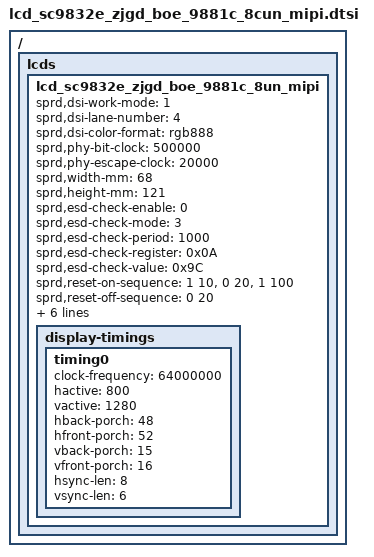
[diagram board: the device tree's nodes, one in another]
/ { lcds {
	lcd_sc9832e_zjgd_boe_9881c_8un_mipi: lcd_sc9832e_zjgd_boe_9881c_8un_mipi {

		sprd,dsi-work-mode = <1>;
		sprd,dsi-lane-number = <4>;
		sprd,dsi-color-format = "rgb888";

		sprd,phy-bit-clock = <500000>;
		sprd,phy-escape-clock = <20000>;

		sprd,width-mm = <68>;
		sprd,height-mm = <121>;

		sprd,esd-check-enable = <0>;
		sprd,esd-check-mode = <3>;
		sprd,esd-check-period = <1000>;
		sprd,esd-check-register = <0x0A>;
		sprd,esd-check-value = <0x9C>;

		sprd,reset-on-sequence = <1 10>, <0 20>, <1 100>;
		sprd,reset-off-sequence = <0 20>;

		sprd,initial-command = [
		 39 00 00 04 FF 98 81 03 
//GIP_1

		 23 00 00 02 01 00 
		 23 00 00 02 02 00 
		 23 00 00 02 03 73 
		 23 00 00 02 04 D7 
		 23 00 00 02 05 00 
		 23 00 00 02 06 08 
		 23 00 00 02 07 11 
		 23 00 00 02 08 00 
		 23 00 00 02 09 3F 
		 23 00 00 02 0a 00 
		 23 00 00 02 0b 00 
		 23 00 00 02 0c 00 
		 23 00 00 02 0d 00 
		 23 00 00 02 0e 00 
		 23 00 00 02 0f 3F 
		 23 00 00 02 10 3F 
		 23 00 00 02 11 00         
		 23 00 00 02 12 00 
		 23 00 00 02 13 00 
		 23 00 00 02 14 00 
		 23 00 00 02 15 00 
		 23 00 00 02 16 00 
		 23 00 00 02 17 00 
		 23 00 00 02 18 00 
		 23 00 00 02 19 00 
		 23 00 00 02 1a 00 
		 23 00 00 02 1b 00 
		 23 00 00 02 1c 00 
		 23 00 00 02 1d 00 
		 23 00 00 02 1e 40 
		 23 00 00 02 1f 80 
		 23 00 00 02 20 06 
		 23 00 00 02 21 01 
		 23 00 00 02 22 00 
		 23 00 00 02 23 00 
		 23 00 00 02 24 00 
		 23 00 00 02 25 00 
		 23 00 00 02 26 00 
		 23 00 00 02 27 00 
		 23 00 00 02 28 33 
		 23 00 00 02 29 33 
		 23 00 00 02 2a 00 
		 23 00 00 02 2b 00 
		 23 00 00 02 2c 00 
		 23 00 00 02 2d 00 
		 23 00 00 02 2e 00 
		 23 00 00 02 2f 00 
		 23 00 00 02 30 00 
		 23 00 00 02 31 00 
		 23 00 00 02 32 00 
		 23 00 00 02 33 00 
		 23 00 00 02 34 00 
		 23 00 00 02 35 00 
		 23 00 00 02 36 00 
		 23 00 00 02 37 00 
		 23 00 00 02 38 00 
		 23 00 00 02 39 00 
		 23 00 00 02 3a 00 
		 23 00 00 02 3b 00 
		 23 00 00 02 3c 00 
		 23 00 00 02 3d 00 
		 23 00 00 02 3e 00 
		 23 00 00 02 3f 00 
		 23 00 00 02 40 00 
		 23 00 00 02 41 00 
		 23 00 00 02 42 00 
		 23 00 00 02 43 00 
		 23 00 00 02 44 00 


//GIP_2
		 23 00 00 02 50 01 
		 23 00 00 02 51 23 
		 23 00 00 02 52 44 
		 23 00 00 02 53 67 
		 23 00 00 02 54 89 
		 23 00 00 02 55 ab 
		 23 00 00 02 56 01 
		 23 00 00 02 57 23 
		 23 00 00 02 58 45 
		 23 00 00 02 59 67 
		 23 00 00 02 5a 89 
		 23 00 00 02 5b ab 
		 23 00 00 02 5c cd 
		 23 00 00 02 5d ef 

//GIP_3
		 23 00 00 02 5e 00 
		 23 00 00 02 5f 0C 
		 23 00 00 02 60 0C 
		 23 00 00 02 61 0F 
		 23 00 00 02 62 0F 
		 23 00 00 02 63 0E 
		 23 00 00 02 64 0E 
		 23 00 00 02 65 06 
		 23 00 00 02 66 07 
		 23 00 00 02 67 0D 
		 23 00 00 02 68 02 
		 23 00 00 02 69 02 
		 23 00 00 02 6a 02 
		 23 00 00 02 6b 02 
		 23 00 00 02 6c 02 
		 23 00 00 02 6d 02 
		 23 00 00 02 6e 0D 
		 23 00 00 02 6f 02 
		 23 00 00 02 70 02 
		 23 00 00 02 71 05 
		 23 00 00 02 72 01 
		 23 00 00 02 73 08 
		 23 00 00 02 74 00 
  
		 23 00 00 02 75 0C 
		 23 00 00 02 76 0C 
		 23 00 00 02 77 0F    
		 23 00 00 02 78 0F 
		 23 00 00 02 79 0E 
		 23 00 00 02 7a 0E 
		 23 00 00 02 7b 06 
		 23 00 00 02 7c 07 
		 23 00 00 02 7d 0D 
		 23 00 00 02 7e 02 
		 23 00 00 02 7f 02 
		 23 00 00 02 80 02  
		 23 00 00 02 81 02 
		 23 00 00 02 82 02 
		 23 00 00 02 83 02 
		 23 00 00 02 84 0D   
		 23 00 00 02 85 02 
		 23 00 00 02 86 02 
		 23 00 00 02 87 05 
		 23 00 00 02 88 01 
		 23 00 00 02 89 08 
		 23 00 00 02 8A 00 



//CMD_Page 4
		 39 00 00 04 FF 98 81 04 

		 23 00 00 02 6E 3B 
		 23 00 00 02 6F 57 
		 23 00 00 02 3A A4 
		 23 00 00 02 8D 1F 
		 23 00 00 02 87 BA 
		 23 00 00 02 B2 D1 
		 23 00 00 02 88 0B 
		 23 00 00 02 38 01 
		 23 00 00 02 39 00 
		 23 00 00 02 B5 07 
		 23 00 00 02 31 75 
		 23 00 00 02 3B 98 
			
//CMD_Page 1
		 39 00 00 04 FF 98 81 01 
		 23 00 00 02 22 0A 
		 23 00 00 02 31 09 
		 23 00 00 02 53 62 
		 23 00 00 02 55 40 
		 23 00 00 02 50 86 
		 23 00 00 02 51 82 
		 23 00 00 02 60 27 
		 23 00 00 02 62 20 


//============Gamma START=============

		 23 00 00 02 A0 00 
		 23 00 00 02 A1 11 
		 23 00 00 02 A2 1F 
		 23 00 00 02 A3 13 
		 23 00 00 02 A4 14 
		 23 00 00 02 A5 28 
		 23 00 00 02 A6 1D 
		 23 00 00 02 A7 1F 
		 23 00 00 02 A8 7A 
		 23 00 00 02 A9 1C 
		 23 00 00 02 AA 2A 
		 23 00 00 02 AB 69 
		 23 00 00 02 AC 1A 
		 23 00 00 02 AD 18 
		 23 00 00 02 AE 4D 
		 23 00 00 02 AF 22 
		 23 00 00 02 B0 29 
		 23 00 00 02 B1 4C 
		 23 00 00 02 B2 5B 
		 23 00 00 02 B3 23 



//Neg Register
		 23 00 00 02 C0 00 
		 23 00 00 02 C1 12 
		 23 00 00 02 C2 1F 
		 23 00 00 02 C3 12 
		 23 00 00 02 C4 15 
		 23 00 00 02 C5 29 
		 23 00 00 02 C6 1D 
		 23 00 00 02 C7 1E 
		 23 00 00 02 C8 78 
		 23 00 00 02 C9 1D 
		 23 00 00 02 CA 29 
		 23 00 00 02 CB 69 
		 23 00 00 02 CC 19 
		 23 00 00 02 CD 18 
		 23 00 00 02 CE 4C 
		 23 00 00 02 CF 21 
		 23 00 00 02 D0 29 
		 23 00 00 02 D1 4C 
		 23 00 00 02 D2 5B 
		 23 00 00 02 D3 23 


//============ Gamma END===========			
			

//CMD_Page 0			
		 39 00 00 04 FF 98 81 00 	
						
			23 00 00 02 35 00 
			 13  78  00  01 11
			 13  05  00  01 29  
			];
		sprd,sleep-in-command = [
			13 0A 00 01 28
			13 78 00 01 10
			];
		sprd,sleep-out-command = [
			13 78 00 01 11
			13 64 00 01 29
			];

		display-timings {
			timing0 {
			clock-frequency = <64000000>;
			hactive = <800>;
			vactive = <1280>;
			hback-porch = <48>;
			hfront-porch = <52>;
			vback-porch = <15>;
			vfront-porch = <16>;
			hsync-len = <8>;
			vsync-len = <6>;
			};
		};
	};
};};

